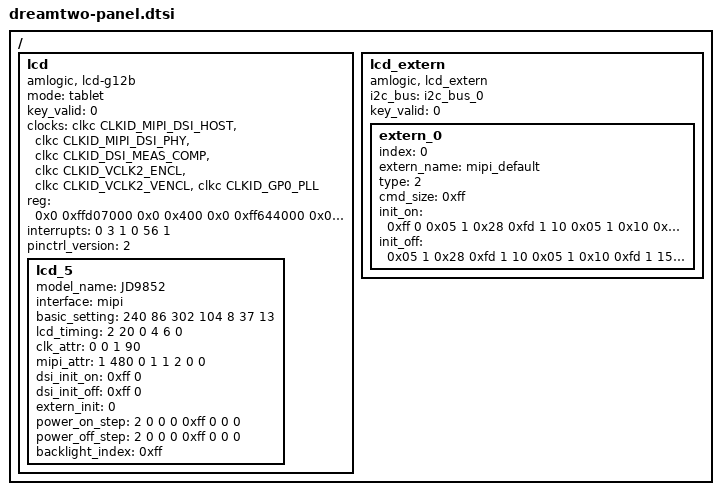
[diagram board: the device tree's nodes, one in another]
/*
 * arch/arm64/boot/dts/amlogic/dreamtwo-panel.dtsi
 *
 * Copyright (C) 2016 Amlogic, Inc. All rights reserved.
 * Copyright (C) 2019 Dream Property GmbH, Germany
 *
 * This program is free software; you can redistribute it and/or modify
 * it under the terms of the GNU General Public License as published by
 * the Free Software Foundation; either version 2 of the License, or
 * (at your option) any later version.
 *
 * This program is distributed in the hope that it will be useful, but WITHOUT
 * ANY WARRANTY; without even the implied warranty of MERCHANTABILITY or
 * FITNESS FOR A PARTICULAR PURPOSE.  See the GNU General Public License for
 * more details.
 *
 */

/ {
	lcd{
		compatible = "amlogic, lcd-g12b";
		mode = "tablet";
		status = "okay";
		key_valid = <0>;
		clocks = <&clkc CLKID_MIPI_DSI_HOST
			&clkc CLKID_MIPI_DSI_PHY
			&clkc CLKID_DSI_MEAS_COMP
			&clkc CLKID_VCLK2_ENCL
			&clkc CLKID_VCLK2_VENCL
			&clkc CLKID_GP0_PLL>;
		clock-names = "dsi_host_gate",
			"dsi_phy_gate",
			"dsi_meas",
			"encl_top_gate",
			"encl_int_gate",
			"gp0_pll";
		reg = <0x0 0xffd07000 0x0 0x400    /* dsi_host */
			0x0 0xff644000 0x0 0x200>; /* dsi_phy */
		interrupts = <0 3 1
			0 56 1>;
		interrupt-names = "vsync","vsync2";
		pinctrl_version = <2>; /* for uboot */

		lcd_5{
			model_name = "JD9852";
			interface = "mipi";
			basic_setting = <240 86 /*h_active, v_active*/
				302 104 /*h_period, v_period*/
				8 /*lcd_bits*/
				37 13>; /*screen_width, screen_height*/
			lcd_timing = <2 20 0 /*hs_width,hs_bp,hs_pol*/
				4 6 0>; /*vs_width,vs_bp,vs_pol*/
			clk_attr = <0 /*fr_adj_type(0=clock,1=htotal,2=vtotal)*/
				0 /*clk_ss_level*/
				1 /*clk_auto_generate*/
				90>; /*frame rate*/
			mipi_attr = <1 /*lane_num*/
				480 /*bit_rate_max(MHz)*/
				0 /*factor(*100, default 0 for auto)*/
				1 /*operation_mode_init(0=video, 1=command)*/
				1 /*operation_mode_display(0=video, 1=command)*/
				2 /*
				   *video_mode_type
				   *(0=sync_pulse,1=sync_event,2=burst)
				   */
				0 /*clk_always_hs(0=disable,1=enable)*/
				0>; /*phy_switch(0=auto,1=standard,2=slow)*/
				/* dsi_init: data_type, num, data... */
			dsi_init_on = <0xff 0>; /*ending*/
			dsi_init_off = <0xff 0>; /*ending*/
				/* extern_init: 0xff for invalid */
			extern_init = <0>;
				/* power step: type,index,value,delay(ms) */
			power_on_step = <
				2 0 0 0
				0xff 0 0 0>; /*ending*/
			power_off_step = <
				2 0 0 0
				0xff 0 0 0>; /*ending*/
			backlight_index = <0xff>;
		};
	};

	lcd_extern{
		compatible = "amlogic, lcd_extern";
		status = "okay";
		i2c_bus = "i2c_bus_0";
		key_valid = <0>;

		extern_0{
			index = <0>;
			extern_name = "mipi_default";/*JD9852*/
			status = "okay";
			type = <2>; /* 0=i2c, 1=spi, 2=mipi */
			cmd_size = <0xff>;
			init_on = <
				0xff 0 /* skip init.. alread done by bootloader */
				0x05 1 0x28
				0xfd 1 10

				0x05 1 0x10
				0xfd 1 10

				0x05 1 0x01
				0xfd 1 10

				0xfd 1 105

				0x29 4 0xdf 0x98 0x51 0xe9
				0x23 2 0x36 0x41
				0xfd 1 1

				0x23 2 0x53 0x00
				0x23 2 0x55 0x00
				0x23 2 0xde 0x00
				0xfd 1 1

				0x29 5 0xb7 0x3c 0x93 0x3c 0x05
				0x29 33 0xc8 0x3f 0x39 0x35 0x2d 0x2d 0x2f 0x2b 0x2c 0x2c 0x2d 0x2d 0x2a 0x29 0x2a 0x28 0x0e 0x3f 0x39 0x35 0x2d 0x2d 0x2f 0x2b 0x2d 0x2c 0x2d 0x2d 0x2a 0x29 0x29 0x28 0x0e
				0x29 4 0xb9 0x33 0x08 0xcc
				0x29 9 0xbb 0x46 0x7a 0x30 0x30 0x6c 0x60 0x50 0x70
				0x29 3 0xbc 0x38 0x3c
				0x29 3 0xc0 0x31 0x20
				0x23 2 0xc1 0x16
				0x29 18 0xc4 0x00 0xa0 0x79 0x0e 0x0a 0x16 0x79 0x0e 0x0a 0x16 0x79 0x0e 0x0a 0x16 0x82 0x00 0x03
				0x29 7 0xd0 0x04 0x0c 0x6b 0x0f 0x01 0x03
				0x29 3 0xd7 0x10 0x00
				0x23 2 0x3a 0x65
				0x29 5 0x2a 0x00 0x00 0x00 0xef
				0x29 5 0x2b 0x00 0x00 0x00 0x55
				0x23 2 0xde 0x02
				0xfd 1 1

				0x29 6 0xb8 0x1d 0xa0 0x2f 0x04 0x33
				0x29 5 0xc1 0x10 0x66 0x66 0x01
				0x23 2 0xde 0x02
				0xfd 1 1

				0x29 4 0xc5 0x4e 0x00 0x00
				0xfd 1 1

				0x29 4 0xca 0x30 0x20 0xf4
				0xfd 1 1

				0x23 2 0xde 0x04
				0xfd 1 1

				0x23 2 0xd3 0x3c
				0xfd 1 1

				0x23 2 0xde 0x00
				0xfd 1 1

				0x23 2 0x35 0x01
				0x29 4 0xdf 0x00 0x00 0x00
				0x29 1 0x21
				0x05 1 0x11
				0xfd 1 150

				0x05 1 0x13
				0x05 1 0x29
				0xfd 1 60

				0xff 0>;    /*ending*/
			init_off = <
				0x05 1 0x28 /* display off */
				0xfd 1 10   /* delay 10ms */
				0x05 1 0x10 /* sleep in */
				0xfd 1 150  /* delay 150ms */
				0xff 0>;    /*ending*/
		};
	};
};/* end of panel */
